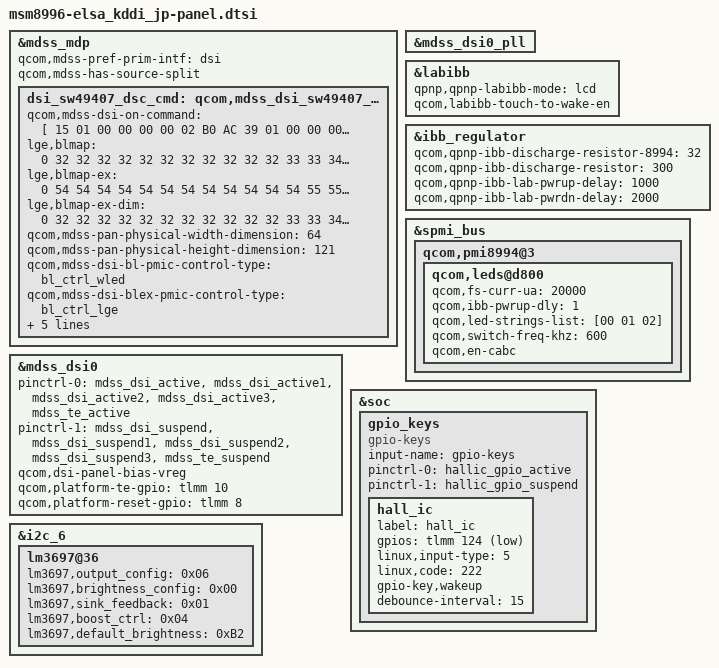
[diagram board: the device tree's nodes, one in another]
/* Copyright (c) 2015, The Linux Foundation. All rights reserved.
 *
 * This program is free software; you can redistribute it and/or modify
 * it under the terms of the GNU General Public License version 2 and
 * only version 2 as published by the Free Software Foundation.
 *
 * This program is distributed in the hope that it will be useful,
 * but WITHOUT ANY WARRANTY; without even the implied warranty of
 * MERCHANTABILITY or FITNESS FOR A PARTICULAR PURPOSE.  See the
 * GNU General Public License for more details.
 */

#include "../dsi-panel-sw49407-dsc-qhd-cmd.dtsi"
#include "../msm8992-panel-backlight-lm3697.dtsi"

&mdss_mdp {
	qcom,mdss-pref-prim-intf = "dsi";
	qcom,mdss-has-source-split;
	dsi_sw49407_dsc_cmd: qcom,mdss_dsi_sw49407_dsc_qhd_cmd {
		qcom,mdss-dsi-on-command = [ /*initset v1.2 modified for anna*/
			/* Manufacturer Command Protection */
			15 01 00 00 00 00 02 B0 AC
			/* Init. Code Version modified for anna*/
			39 01 00 00 00 00 03 D7 2A 0F
			/*Left Side GIP pad setting*/
			39 01 00 00 00 00 0E E5 1A 0D 0C 0E 1A 1A 01 05 07 09 0B 1A 11
			/*Right Side GIP pad setting*/
			39 01 00 00 00 00 0E E6 1A 0D 0C 0E 1A 1A 00 04 06 08 0A 1A 11
			/*Left Side Mux Pad Setting*/
			39 01 00 00 00 00 07 E7 18 17 16 15 14 13
			/*Right Side Mux Pad Setting*/
			39 01 00 00 00 00 07 E8 18 17 16 15 14 13
			/* Page Address Set */
			39 01 00 00 00 00 05 2B 00 00 0A 9F
			/* Partial Area Set */
			39 01 00 00 00 00 05 30 00 00 00 9F
			/* TE line */
			39 01 00 00 00 00 03 44 0A 8F
			/* Tearing Effect Line on */
			15 01 00 00 00 00 02 35 00
			/* Write Display Brightness */
			15 01 00 00 00 00 02 51 ff
			/* Write Control Display */
			15 01 00 00 00 00 02 53 2C
			/* Write Content Adaptive Brightness Control */
			15 01 00 00 00 00 02 55 81
			/* Display Control 1 */
			39 01 00 00 00 00 08 B3 0A 07 28 C8 1A 94 02
			/* Display Control 2 */
			39 01 00 00 00 00 0C B4 93 08 00 0C 0C 0C 0C 18 18 18 18
			/* Display Control 3 */
			39 01 00 00 00 00 0F B5 28 14 2A C8 36 08 00 0A 00 C0 D0 50 05 05
			/* Display Control 4 */
			39 01 00 00 00 00 09 B6 1F 0F 10 C0 00 10 C0 00
			/* Panel Setting */
			39 01 00 00 00 00 05 B7 61 75 EA A9
			/* Touch Timing Control */
			39 01 00 00 00 00 1F B8 70 02 90 40 BF F0 8B 00 00 18 33 04 01 40 01 45 F8 C1 21 00 00 10 01 15 01 0A A0 0A 0A 00
			/* Touch Source Setting */
			39 01 00 00 00 00 06 B9 64 64 2A 3F EE
			/* Backlight Control */
			39 01 00 00 00 00 07 BA 23 67 70 78 7F 80
			/* Internal Oscillator Setting */
			39 01 00 00 00 00 08 C0 98 08 0F 1D FD 68 92
			/* Power Control 1 */
			39 01 00 00 00 00 07 C1 01 00 F0 C2 CF 0C
			/* Power Control 2 */
			39 01 00 00 00 00 05 C2 CC 44 44 40
			/* Power Control 4 */
			39 01 00 00 00 00 08 C3 35 44 22 26 21 35 DD
			/* Power Control 5 */
			39 01 00 00 00 00 07 C5 A2 38 28 54 D4 0E
			/* Vcom Setting modified for anna*/
			//39 01 00 00 00 00 03 C6 1F 01
			/* Power Sequence Option Configuration */
			39 01 00 00 00 00 06 C9 05 5D 03 04 01
			/* APO control */
			39 01 00 00 00 00 03 CA 9F 00
			/* LFD Control */
			39 01 00 00 00 00 06 CB F3 90 3D 3D CC
			/* Tail TFT Setting */
			39 01 00 00 00 00 06 CC 14 50 50 90 41
			/* U2 Control */
			39 01 00 00 00 00 04 CD 86 40 07
			/* Positive Gamma Curve for Red modified for anna*/
			39 01 00 00 00 00 0E D0 00 12 1F 2E 39 42 4C 41 33 23 15 00 03
			/* Negative Gamma Curve for Red modified for anna*/
			39 01 00 00 00 00 0E D1 00 12 1F 2E 39 42 4C 41 33 23 15 00 03
			/* Positive Gamma Curve for Green modified for anna*/
			39 01 00 00 00 00 0E D2 00 12 1E 2D 38 41 4D 44 34 23 15 00 03
			/* Negative Gamma Curve for Green modified for anna*/
			39 01 00 00 00 00 0E D3 00 12 1E 2D 38 41 4D 44 34 23 15 00 03
			/* Positive Gamma Curve for Blue modified for anna*/
			39 01 00 00 00 00 0E D4 00 12 1F 2E 39 42 4C 41 33 23 15 00 03
			/* Negative Gamma Curve for Blue modified for anna*/
			39 01 00 00 00 00 0E D5 00 12 1F 2E 39 42 4C 41 33 23 15 00 03
			/* Test1 */
			39 01 00 00 00 00 05 ED 61 6A 00 82
			/* CABC Test */
			39 01 00 00 00 00 18 F9 20 40 60 80 A0 C0 E0 10 14 14 14 14 14 04 00 B4 C0 CD DC E8 F0 F7 FF
			/* CABC Test */
			39 01 00 00 00 00 0F FA 88 22 22 22 10 42 32 26 02 08 0A A0 52 D0
			/* IE Setting1 */
			39 01 00 00 00 00 03 F0 82 00
			/* IE Setting2 */
			39 01 00 00 00 00 05 F2 01 00 24 00
			/* IE Setting3 */
			39 01 00 00 00 00 18 F3 00 43 83 C0 FF 00 00 40 80 C0 FF 00 00 40 80 C0 00 00 00 40 80 C0 FF
			/* reader mode */
			39 01 00 00 00 00 11 F4 40 40 40 40 40 40 40 40 00 00 00 00 00 00 00 00
			39 01 00 00 00 00 11 F5 40 40 40 40 40 40 40 40 00 00 00 00 00 00 00 00
			39 01 00 00 00 00 11 F6 40 40 40 40 40 40 40 40 00 00 00 00 00 00 00 00
			/* Normal Display mode on */
			05 01 00 00 00 00 01 13
			];

		lge,blmap = <
			0
			32 32 32 32 32 32 32 32 32 32
			32 33 33 34 34 34 35 35 35 36
			36 37 37 39 40 42 43 45 47 48
			50 51 53 54 56 58 61 63 66 68
			71 73 75 78 80 83 85 88 90 94
			99 103 107 111 116 120 124 128 133 137
			141 148 154 161 168 175 181 188 195 202
			208 215 222 229 235 242 249 256 262 269
			276 283 289 296 305 313 322 330 339 347
			356 364 373 381 390 398 408 418 429 439
			449 459 469 479 490 500 510 520 531 542
			553 564 575 586 596 607 618 629 640 651
			662 675 687 700 712 725 738 750 763 776
			788 801 813 826 840 855 869 883 898 912
			926 940 955 969 983 998 1012 1030 1047 1065
			1082 1100 1118 1135 1153 1170 1188 1205 1223 1245
			1267 1289 1311 1333 1354 1376 1398 1420 1442 1461
			1482 1502 1523 1543 1564 1584 1605 1625 1646 1666
			1687 1707 1728 1750 1773 1795 1817 1840 1862 1884
			1906 1929 1951 1973 1996 2018 2045 2072 2100 2127
			2154 2181 2208 2235 2263 2290 2317 2344 2376 2409
			2441 2473 2506 2538 2571 2603 2635 2668 2700 2732
			2764 2796 2828 2860 2892 2924 2956 2988 3020 3052
			3084 3116 3147 3179 3210 3242 3273 3305 3337 3368
			3400 3431 3463 3494 3506 3550 3593 3637 3680 3724
			3768 3811 3855 3898 3942
		>;

		lge,blmap-ex = <
			0
			54 54 54 54 54 54 54 54 54 54
			54 54 55 55 55 55 56 56 56 56
			57 57 57 58 59 60 61 62 63 64
			65 66 67 68 69 70 71 72 74 75
			76 77 78 79 80 82 83 84 85 86
			87 88 89 90 91 91 92 93 94 95
			96 97 98 100 101 102 103 104 105 107
			108 109 110 111 112 113 114 116 117 118
			119 120 121 122 123 124 125 126 127 128
			128 129 130 131 132 133 134 135 136 136
			137 138 139 140 141 141 142 143 144 145
			145 146 147 148 148 149 150 151 151 152
			153 154 154 155 155 156 157 157 158 159
			159 160 160 161 162 162 163 164 164 165
			166 167 167 168 169 169 170 171 171 172
			172 173 173 174 174 175 175 176 176 177
			177 178 178 179 179 180 180 181 181 182
			182 183 183 184 184 184 185 185 185 186
			186 187 187 187 188 188 189 189 189 190
			190 190 191 191 192 192 192 193 193 194
			194 195 195 195 196 196 197 197 197 198
			198 199 199 200 200 201 201 202 202 202
			203 203 204 204 205 205 205 206 206 207
			207 207 208 208 208 209 209 210 210 210
			211 211 211 212 212 213 213 214 214 215
			215 216 216 217 217
		>;

		lge,blmap-ex-dim = <
			0
			32 32 32 32 32 32 32 32 32 32
			32 33 33 34 34 34 35 35 35 36
			36 37 37 38 39 40 41 42 44 45
			46 47 48 49 50 51 53 54 55 56
			58 59 60 62 63 64 65 67 68 69
			71 72 73 74 76 77 78 79 81 82
			83 84 86 87 88 90 91 93 94 95
			97 98 99 100 101 102 103 105 106 107
			108 109 110 111 112 113 114 114 115 116
			117 118 119 119 120 121 122 123 124 124
			125 126 127 128 129 129 130 131 132 132
			133 134 134 135 136 137 137 138 139 139
			140 141 141 142 142 143 143 144 144 145
			145 146 146 147 148 148 149 149 150 150
			151 151 152 152 153 153 154 155 155 156
			156 157 158 158 159 159 160 160 161 162
			162 163 164 164 165 165 166 167 167 168
			169 169 170 170 171 171 172 172 173 173
			174 174 175 175 176 176 177 177 177 178
			178 178 179 179 180 180 181 181 182 182
			183 183 184 184 185 185 186 186 186 187
			187 188 188 189 189 190 190 191 191 191
			192 192 193 193 194 194 194 195 195 196
			196 196 197 197 197 198 198 199 199 199
			200 200 200 201 201 201 202 202 203 203
			203 204 204 205 205
		>;
               qcom,mdss-pan-physical-width-dimension = <64>;
               qcom,mdss-pan-physical-height-dimension = <121>;
	};
};

&mdss_dsi0 {
	pinctrl-names = "mdss_default", "mdss_sleep";
	pinctrl-0 = <&mdss_dsi_active &mdss_dsi_active1 &mdss_dsi_active2 &mdss_dsi_active3 &mdss_te_active>;
	pinctrl-1 = <&mdss_dsi_suspend &mdss_dsi_suspend1 &mdss_dsi_suspend2 &mdss_dsi_suspend3 &mdss_te_suspend>;
	qcom,dsi-panel-bias-vreg;
	qcom,platform-te-gpio = <&tlmm 10 0>;
	qcom,platform-reset-gpio = <&tlmm 8 0>;

	/delete-property/vddio-supply;
};

&mdss_dsi0_pll {
		/delete-property/ memory-region;
};

&labibb {
	status = "ok";
	qpnp,qpnp-labibb-mode = "lcd";
	qcom,labibb-touch-to-wake-en;
};

&ibb_regulator {
	qcom,qpnp-ibb-discharge-resistor-8994 = <32>;
	qcom,qpnp-ibb-discharge-resistor = <300>;
	qcom,qpnp-ibb-lab-pwrup-delay = <1000>;
	qcom,qpnp-ibb-lab-pwrdn-delay = <2000>;
};

&dsi_sw49407_dsc_cmd {
	qcom,mdss-dsi-bl-pmic-control-type = "bl_ctrl_wled";
	qcom,mdss-dsi-blex-pmic-control-type = "bl_ctrl_lge";
	qcom,mdss-dsi-bl-min-level = <1>;
	qcom,mdss-dsi-bl-max-level = <4095>;
	qcom,cont-splash-enabled;
	qcom,panel-supply-entries = <&dsi_panel_pwr_supply>;
};

&spmi_bus {
	qcom,pmi8994@3 {
		qcom,leds@d800 {
			qcom,fs-curr-ua = <20000>;
			qcom,ibb-pwrup-dly = <1>;
			qcom,led-strings-list = [00 01 02];
			qcom,switch-freq-khz = <600>;
			qcom,en-cabc;
		};
	};
};

&soc {
	gpio_keys {
		compatible = "gpio-keys";
		input-name = "gpio-keys";

		pinctrl-names = "tlmm_gpio_key_active","tlmm_gpio_key_suspend";
		pinctrl-0 = <&hallic_gpio_active>;
		pinctrl-1 = <&hallic_gpio_suspend>;

		hall_ic {
			label = "hall_ic";
			gpios = <&tlmm 124 0x1>;
			linux,input-type = <5>;
			linux,code = <222>;
			gpio-key,wakeup;
			debounce-interval = <15>;
		};
	};
};

&i2c_6{
	lm3697@36 {
		lm3697,output_config = <0x06>;
		lm3697,brightness_config = <0x00>;
		lm3697,sink_feedback = <0x01>;
		lm3697,boost_ctrl = <0x04>;
		lm3697,default_brightness = <0xB2>;
	};
};
